# AM13E23019 register map
Vendor: Texas Instruments; File version: 1.0
CPU: CM33 r0p1, little endian, MPU, FPU, VTOR, 4 interrupt priority bits
Registers are 32-bit, read-write, reset 0x0 unless marked. A register's access mark holds for its fields unless they carry their own. Offsets are from the block's base; [hi:lo] are bit positions; lines under a group give offsets from that group; {n}, {i} and the like mark numbered series.

## PWMXBAR — EPWM_XBAR module
Base 0x40469000
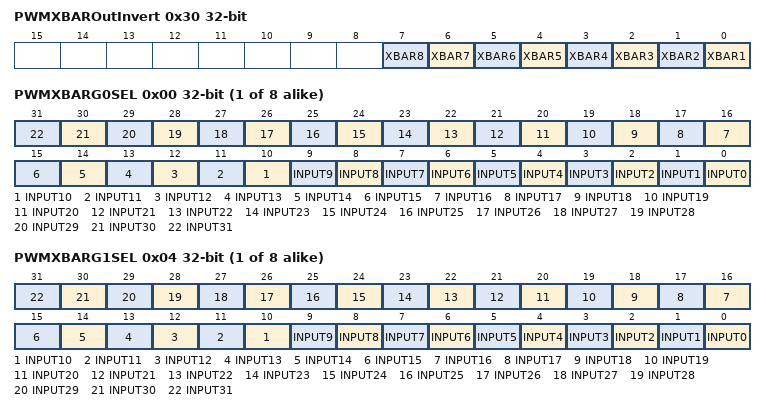
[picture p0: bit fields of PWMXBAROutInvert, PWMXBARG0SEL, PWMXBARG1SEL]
0x30 PWMXBAROutInvert — Output Signal Invert Select
  [n-1] XBAR{n} (n=1..8) — Invert XBAR Output Select for XBAR{n}
0x80 PWMXBARLock — Configuration Lock register
  [0] LOCK — Locks the configuration for EPWM-XBAR
{0x100+0x40*i} EPWM_XBAR_REGS_RegisterFile0[{i}] (i=0..7) group
  0x00 PWMXBARG0SEL — PWMXBAR G0 Input Select
    [n] INPUT{n} (n=0..31) — Select bit for INPUT{n}
  0x04 PWMXBARG1SEL — PWMXBAR G1 Input Select
    [n] INPUT{n} (n=0..31) — Select bit for INPUT{n}

## OUTPUTXBAR — OUTPUTXBAR module
Base 0x4046A000
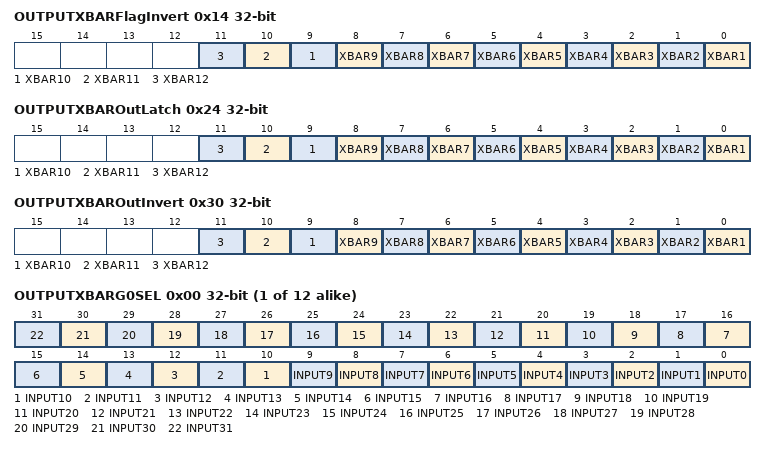
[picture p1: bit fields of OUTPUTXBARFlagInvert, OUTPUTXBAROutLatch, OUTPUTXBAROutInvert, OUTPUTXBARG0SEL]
0x14 OUTPUTXBARFlagInvert — Output Signal inversion register
  [n-1] XBAR{n} (n=1..12) — Invert XBAR Output Before Latch for XBAR{n}
0x24 OUTPUTXBAROutLatch — Output Signal Select Latch
  [n-1] XBAR{n} (n=1..12) — XBAR Output Latch Select for XBAR{n}
0x30 OUTPUTXBAROutInvert — Output Signal Invert Select
  [n-1] XBAR{n} (n=1..12) — Invert XBAR Output for XBAR{n}
0x80 OUTPUTXBARLock — Configuration Lock register
  [0] LOCK — Locks the configuration for EOUTPUT-XBAR
{0x100+0x40*i} OUTPUTXBAR_REGS_RegisterFile0[{i}] (i=0..11) group
  0x00 OUTPUTXBARG0SEL — OUTPUTXBAR G0 Input Select
    [n] INPUT{n} (n=0..31) — Select bit for INPUT{n}
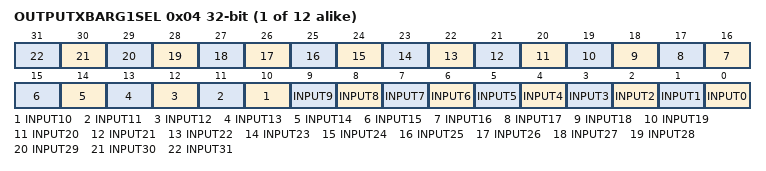
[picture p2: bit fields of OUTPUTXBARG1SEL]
  0x04 OUTPUTXBARG1SEL — OUTPUTXBAR G1 Input Select
    [n] INPUT{n} (n=0..31) — Select bit for INPUT{n}

## SYNC — SYNC_SOC module
Base 0x4046B000
0x00 SYNCSELECT — Sync Input and Output Select Register
  [28:24] SYNCOUT — Select EXT Syncout Source
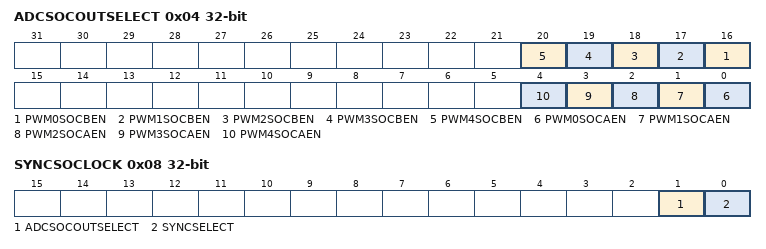
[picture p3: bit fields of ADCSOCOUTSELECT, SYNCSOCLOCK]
0x04 ADCSOCOUTSELECT — External ADCSOC Select Register
  [n+16] PWM{n}SOCBEN (n=0..4) — PWM{n}SOCBEN Enable for ADCSOCBOn
  [n] PWM{n}SOCAEN (n=0..4) — PWM{n}SOCAEN Enable for ADCSOCAOn
0x08 SYNCSOCLOCK — SYNCSEL and EXTADCSOC Select Lock register
  [1] ADCSOCOUTSELECT — ADCSOCOUTSELECT Register Lock bit
  [0] SYNCSELECT — SYNCSEL Register Lock bit

## OUTPUTXBAR0_FLAGS — OUTPUTXBAR_FLAG module
Base 0x40470000
Same registers: OUTPUTXBAR1_FLAGS 0x40471000, OUTPUTXBAR2_FLAGS 0x40472000, OUTPUTXBAR3_FLAGS 0x40473000, OUTPUTXBAR4_FLAGS 0x40474000, OUTPUTXBAR5_FLAGS 0x40475000, OUTPUTXBAR6_FLAGS 0x40476000, OUTPUTXBAR7_FLAGS 0x40477000
0x10 OUTPUTXBARStatus ro — Output Signal Status register
  [0] STS — Output Signal Status
0x18 OUTPUTXBARFlag ro — Output latched flag register
  [0] FLG — Output Signal Latched Flag Status
0x1C OUTPUTXBARFlagClear — Output latched flag clear register
  [0] FLG — Output Signal Latched Flag Clear
0x20 OUTPUTXBARFlagForce — Output latched flag Force register
  [0] FLG — Output Signal Latched Flag Force

## INPUTXBAR_FLAGS — INPUT_FLAG_XBAR module
Base 0x40490000
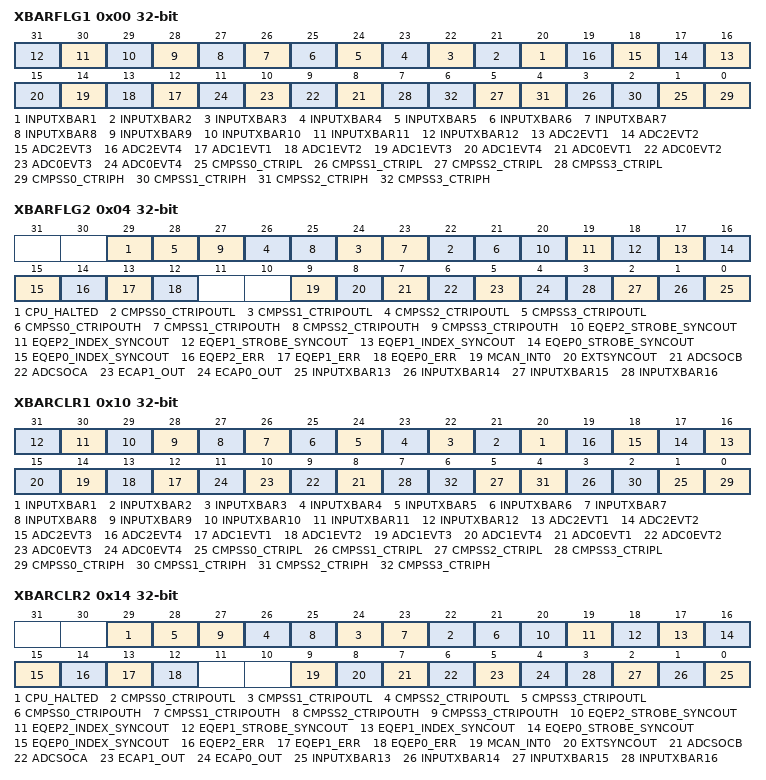
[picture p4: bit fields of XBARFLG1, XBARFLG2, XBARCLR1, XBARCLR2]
0x00 XBARFLG1 ro — X-Bar Input Flag Register 1
  [n+19] INPUTXBAR{n} (n=1..12) — Input Flag for INPUTXBAR{n} Signal
  [n+15] ADC2EVT{n} (n=1..4) — Input Flag for ADC2EVT{n} Signal
  [n+11] ADC1EVT{n} (n=1..4) — Input Flag for ADC1EVT{n} Signal
  [n+7] ADC0EVT{n} (n=1..4) — Input Flag for ADC0EVT{n} Signal
  [2n+1] CMPSS{n}_CTRIPL (n=0..3) — Input Flag for CMPSS{n}_CTRIPL Signal
  [2n] CMPSS{n}_CTRIPH (n=0..3) — Input Flag for CMPSS{n}_CTRIPH Signal
0x04 XBARFLG2 ro — X-Bar Input Flag Register 2
  [29] CPU_HALTED — Input Flag for CPU_HALTED Signal
  [2n+22] CMPSS{n}_CTRIPOUTL (n=0..3) — Input Flag for CMPSS{n}_CTRIPOUTL Signal
  [2n+21] CMPSS{n}_CTRIPOUTH (n=0..3) — Input Flag for CMPSS{n}_CTRIPOUTH Signal
  [20] EQEP2_STROBE_SYNCOUT — Input Flag for EQEP2_STROBE_SYNCOUT Signal
  [19] EQEP2_INDEX_SYNCOUT — Input Flag for EQEP2_INDEX_SYNCOUT Signal
  [18] EQEP1_STROBE_SYNCOUT — Input Flag for EQEP1_STROBE_SYNCOUT Signal
  [17] EQEP1_INDEX_SYNCOUT — Input Flag for EQEP1_INDEX_SYNCOUT Signal
  [16] EQEP0_STROBE_SYNCOUT — Input Flag for EQEP0_STROBE_SYNCOUT Signal
  [15] EQEP0_INDEX_SYNCOUT — Input Flag for EQEP0_INDEX_SYNCOUT Signal
  [14] EQEP2_ERR — Input Flag for EQEP2_ERR Signal
  [13] EQEP1_ERR — Input Flag for EQEP1_ERR Signal
  [12] EQEP0_ERR — Input Flag for EQEP0_ERR Signal
  [9] MCAN_INT0 — Input Flag for MCAN_INT0 Signal
  [8] EXTSYNCOUT — Input Flag for EXTSYNCOUT Signal
  [7] ADCSOCB — Input Flag for ADCSOCB Signal
  [6] ADCSOCA — Input Flag for ADCSOCA Signal
  [5] ECAP1_OUT — Input Flag for ECAP1_OUT Signal
  [4] ECAP0_OUT — Input Flag for ECAP0_OUT Signal
  [n-13] INPUTXBAR{n} (n=13..16) — Input Flag for INPUTXBAR{n} Signal
0x10 XBARCLR1 — X-Bar Input Flag Clear Register 1
  [n+19] INPUTXBAR{n} (n=1..12) — Input Flag Clear for INPUTXBAR{n} Signal
  [n+15] ADC2EVT{n} (n=1..4) — Input Flag Clear for ADC2EVT{n} Signal
  [n+11] ADC1EVT{n} (n=1..4) — Input Flag Clear for ADC1EVT{n} Signal
  [n+7] ADC0EVT{n} (n=1..4) — Input Flag Clear for ADC0EVT{n} Signal
  [2n+1] CMPSS{n}_CTRIPL (n=0..3) — Input Flag Clear for CMPSS{n}_CTRIPL Signal
  [2n] CMPSS{n}_CTRIPH (n=0..3) — Input Flag Clear for CMPSS{n}_CTRIPH Signal
0x14 XBARCLR2 — X-Bar Input Flag Clear Register 2
  [29] CPU_HALTED — Input Flag Clear for CPU_HALTED Signal
  [2n+22] CMPSS{n}_CTRIPOUTL (n=0..3) — Input Flag Clear for CMPSS{n}_CTRIPOUTL Signal
  [2n+21] CMPSS{n}_CTRIPOUTH (n=0..3) — Input Flag Clear for CMPSS{n}_CTRIPOUTH Signal
  [20] EQEP2_STROBE_SYNCOUT — Input Flag Clear for EQEP2_STROBE_SYNCOUT Signal
  [19] EQEP2_INDEX_SYNCOUT — Input Flag Clear for EQEP2_INDEX_SYNCOUT Signal
  [18] EQEP1_STROBE_SYNCOUT — Input Flag Clear for EQEP1_STROBE_SYNCOUT Signal
  [17] EQEP1_INDEX_SYNCOUT — Input Flag Clear for EQEP1_INDEX_SYNCOUT Signal
  [16] EQEP0_STROBE_SYNCOUT — Input Flag Clear for EQEP0_STROBE_SYNCOUT Signal
  [15] EQEP0_INDEX_SYNCOUT — Input Flag Clear for EQEP0_INDEX_SYNCOUT Signal
  [14] EQEP2_ERR — Input Flag Clear for EQEP2_ERR Signal
  [13] EQEP1_ERR — Input Flag Clear for EQEP1_ERR Signal
  [12] EQEP0_ERR — Input Flag Clear for EQEP0_ERR Signal
  [9] MCAN_INT0 — Input Flag Clear for MCAN_INT0 Signal
  [8] EXTSYNCOUT — Input Flag Clear for EXTSYNCOUT Signal
  [7] ADCSOCB — Input Flag Clear for ADCSOCB Signal
  [6] ADCSOCA — Input Flag Clear for ADCSOCA Signal
  [5] ECAP1_OUT — Input Flag Clear for ECAP1_OUT Signal
  [4] ECAP0_OUT — Input Flag Clear for ECAP0_OUT Signal
  [n-13] INPUTXBAR{n} (n=13..16) — Input Flag Clear for INPUTXBAR{n} Signal
